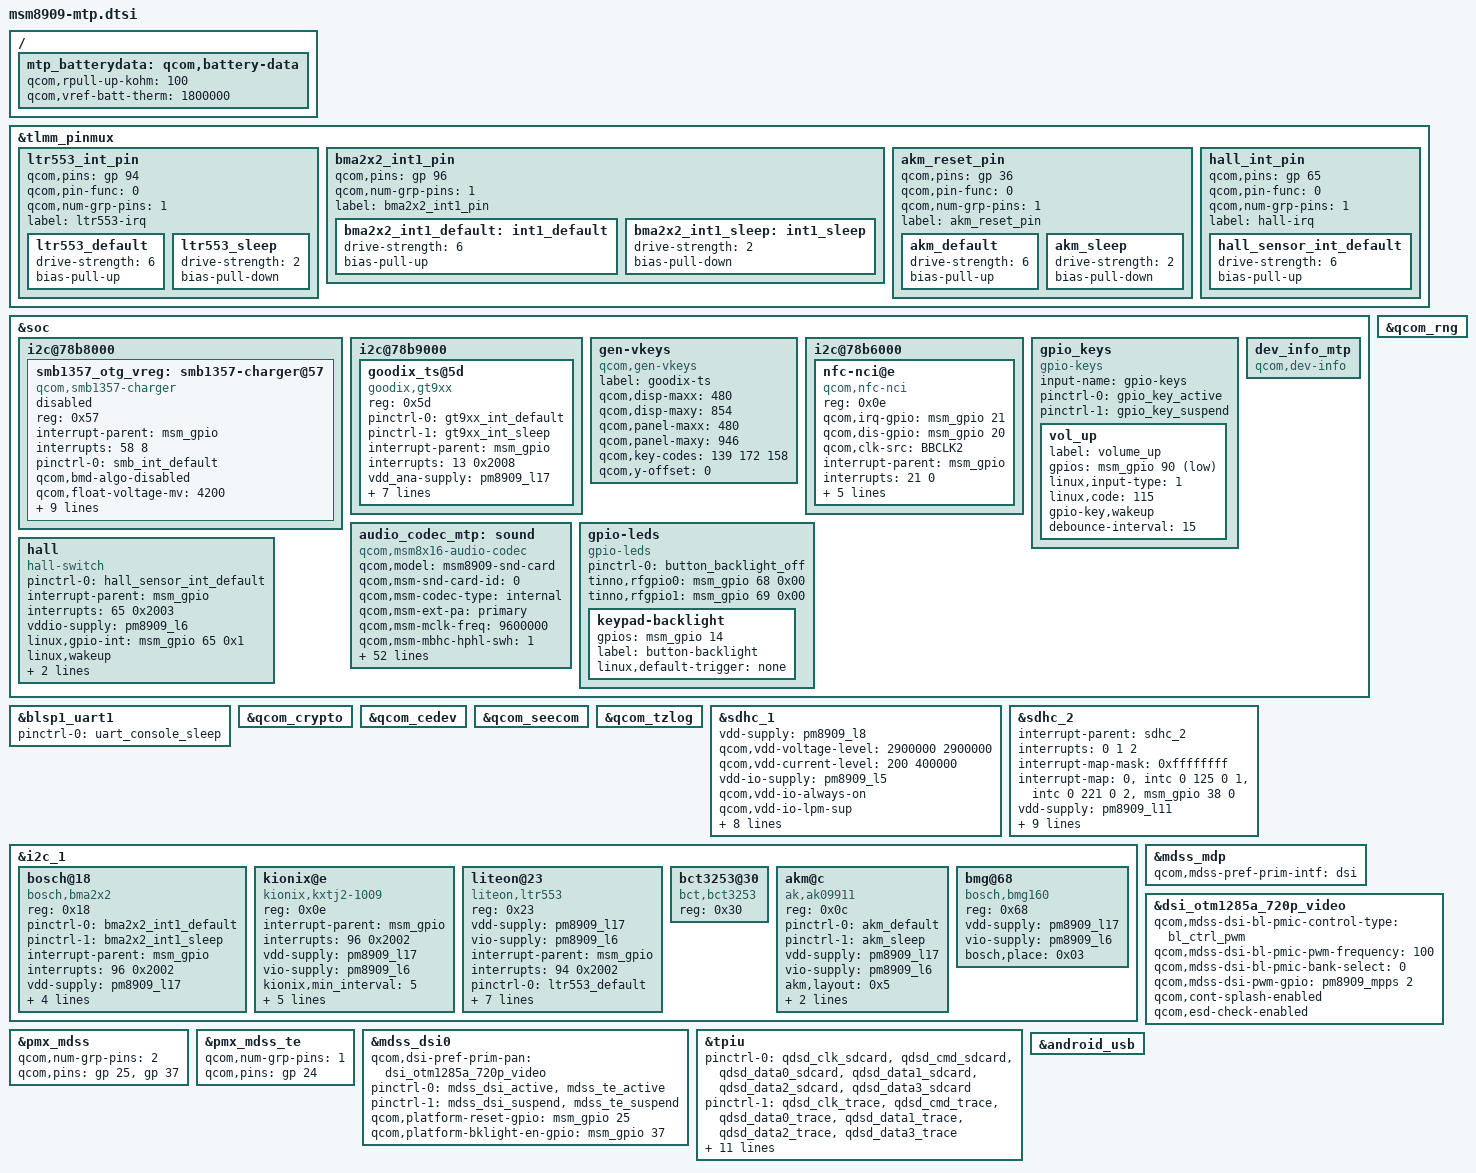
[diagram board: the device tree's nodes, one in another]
/* Copyright (c) 2014-2015, The Linux Foundation. All rights reserved.
 *
 * This program is free software; you can redistribute it and/or modify
 * it under the terms of the GNU General Public License version 2 and
 * only version 2 as published by the Free Software Foundation.
 *
 * This program is distributed in the hope that it will be useful,
 * but WITHOUT ANY WARRANTY; without even the implied warranty of
 * MERCHANTABILITY or FITNESS FOR A PARTICULAR PURPOSE.  See the
 * GNU General Public License for more details.
 */

#include "msm8909.dtsi"
#include "msm8909-pinctrl.dtsi"
#include "msm8909-camera-sensor-mtp.dtsi"
//[JST_SRC START BY CY][20150226][Sensors dts config]
&tlmm_pinmux {

	ltr553_int_pin {
		qcom,pins = <&gp 94>;
		qcom,pin-func = <0>;
		qcom,num-grp-pins = <1>;
		label = "ltr553-irq";
		ltr553_default: ltr553_default {
			drive-strength = <6>;
			bias-pull-up;
		};
		ltr553_sleep: ltr553_sleep {
			drive-strength = <2>;
			bias-pull-down;
		};

	};

	bma2x2_int1_pin {
		qcom,pins = <&gp 96>;
		qcom,num-grp-pins = <1>;
		label = "bma2x2_int1_pin";
		bma2x2_int1_default: int1_default {
			  drive-strength = <6>;
			  bias-pull-up;
		};
		bma2x2_int1_sleep: int1_sleep {
			  drive-strength = <2>;
			  bias-pull-down;
		};
	};

	akm_reset_pin {
		qcom,pins = <&gp 36>;
		qcom,pin-func = <0>;
		qcom,num-grp-pins = <1>;
		label = "akm_reset_pin";
		akm_default: akm_default {
			drive-strength = <6>;
			bias-pull-up;
		};
		akm_sleep: akm_sleep {
			drive-strength = <2>;
			bias-pull-down;
		};
	};
	
	hall_int_pin {
		qcom,pins = <&gp 65>;
		qcom,pin-func = <0>;
		qcom,num-grp-pins = <1>;
		label = "hall-irq";
		hall_sensor_int_default: hall_sensor_int_default {
			drive-strength = <6>;
			bias-pull-up;
		};
	};
};
//[JST_SRC END][20150226]
&soc {
	/*
	 * DT node to add support for SMB135x charger and integrate
	 * with VM-BMS.
	 */
	i2c@78b8000 {
		smb1357_otg_vreg: smb1357-charger@57 {
			compatible = "qcom,smb1357-charger";
			reg = <0x57>;
			interrupt-parent = <&msm_gpio>;
			interrupts = <58 8>;
			pinctrl-names = "default";
			pinctrl-0 = <&smb_int_default>;

			qcom,bmd-algo-disabled;
			qcom,float-voltage-mv = <4200>;
			qcom,charging-timeout = <1536>;
			qcom,recharge-thresh-mv = <100>;
			regulator-name = "smb1357_otg_vreg";
			qcom,soft-vfloat-comp-disabled;
			qcom,thermal-mitigation = <1500 700 600 0>;

			qcom,bms-psy-name = "bms";

			/*
			 * Disable SMB1357 based charging termination as BMS
			 * controls charging.
			 */
			qcom,iterm-disabled;

			/*
			 * Disable charge inhibit feature to start chargin on
			 * charger insertion independent of battery voltage.
			 */
			qcom,inhibit-disabled;

			/* BMS is controlling charging/re-charge */
			qcom,bms-controlled-charging;

			/*
			 * To enable charger node:
			 * set status = "ok" and
			 * add 'qcom,use-external-charger' to pm8909_chg node
			 */
			status = "disabled";
		};
	};

	i2c@78b9000 { /* BLSP1 QUP5 */
	/*	synaptics@20 {
			compatible = "synaptics,dsx";
			reg = <0x20>;
			interrupt-parent = <&msm_gpio>;
			interrupts = <13 0x2008>;
			avdd-supply = <&pm8909_l17>;
			vdd-supply = <&pm8909_l6>;
			pinctrl-names = "pmx_ts_active","pmx_ts_suspend","pmx_ts_release";
			pinctrl-0 = <&ts_int_active &ts_reset_active>;
			pinctrl-1 = <&ts_int_suspend &ts_reset_suspend>;
			pinctrl-2 = <&ts_release>;
			synaptics,irq-gpio = <&msm_gpio 13 0x2008>;
			synaptics,reset-gpio = <&msm_gpio 12 0x0>;
			synaptics,disable-gpios;
			synaptics,display-coords = <0 0 719 1279>;
			synaptics,panel-coords = <0 0 719 1405>;
		};*/
		goodix_ts@5d {
			compatible = "goodix,gt9xx";
			reg = <0x5d>;
			pinctrl-names ="gt9xx_int_pin_active" ,"gt9xx_int_pin_suspend";
			pinctrl-0 = <&gt9xx_int_default>;
			pinctrl-1 = <&gt9xx_int_sleep>;			
			interrupt-parent = <&msm_gpio>;
			interrupts = <13 0x2008>;
			vdd_ana-supply = <&pm8909_l17>;
			vcc_i2c-supply = <&pm8909_l6>;
			goodix,rst-gpio = <&msm_gpio 12 0x00>;
			goodix,irq-gpio = <&msm_gpio 13 0x00>;
			goodix,cfg-group0 = [ 
  45  D0  02  00  05  05  05  40  01  08  28
  08  50  32  03  09  00  00  FF  67  01  00
  06  00  00  00  00  8A  2A  0B  29  2B  D5
  09  00  42  00  42  33  1D  00  01  00  00
  00  00  00  32  15  00  2B  14  50  94  C5
  02  00  00  00  04  D3  17  00  A7  1E  00
  82  28  00  67  35  00  53  46  00  53  00
  00  00  00  00  00  00  00  00  00  00  00
  00  00  00  00  00  00  00  00  00  00  00
  00  00  00  00  00  00  00  00  0C  00  00
  00  00  12  10  0E  08  0A  0C  14  16  02
  04  06  FF  FF  FF  00  00  00  00  00  00
  00  00  00  00  06  00  00  00  00  00  22
  16  21  18  20  1C  1F  1D  24  1E  12  00
  02  10  04  0F  06  0C  08  0A  FF  FF  FF
  FF  FF  FF  00  00  00  F4  FF  FF  FF  FF
  FF  FF  FF  FF  7F  FF  FF  FF  0F  01];

			goodix,cfg-group1 = [
  45  D0  02  00  05  05  05  40  01  08  28
  08  50  32  03  09  00  00  FF  67  01  00
  06  00  00  00  00  8A  2A  0B  29  2B  D5
  09  00  42  00  42  33  1D  00  01  00  00
  00  00  00  32  15  00  2B  14  50  94  C5
  02  00  00  00  04  D3  17  00  A7  1E  00
  82  28  00  67  35  00  53  46  00  53  00
  00  00  00  00  00  00  00  00  00  00  00
  00  00  00  00  00  00  00  00  00  00  00
  00  00  00  00  00  00  00  00  0C  00  00
  00  00  12  10  0E  08  0A  0C  14  16  02
  04  06  FF  FF  FF  00  00  00  00  00  00
  00  00  00  00  06  00  00  00  00  00  22
  16  21  18  20  1C  1F  1D  24  1E  12  00
  02  10  04  0F  06  0C  08  0A  FF  FF  FF
  FF  FF  FF  00  00  00  F4  FF  FF  FF  FF
  FF  FF  FF  FF  7F  FF  FF  FF  0F  01];
		};

	};

	gen-vkeys {
		compatible = "qcom,gen-vkeys";
		label = "goodix-ts";
		qcom,disp-maxx = <480>;
		qcom,disp-maxy = <854>;
		qcom,panel-maxx = <480>;
		qcom,panel-maxy = <946>;
		qcom,key-codes = <139 172 158>;
		qcom,y-offset = <0>;
	};

	i2c@78b6000 { /* BLSP1 QUP2 */
		nfc-nci@e {
			compatible = "qcom,nfc-nci";
			reg = <0x0e>;
			qcom,irq-gpio = <&msm_gpio 21 0x00>;
			qcom,dis-gpio = <&msm_gpio 20 0x00>;
			qcom,clk-src = "BBCLK2";
			interrupt-parent = <&msm_gpio>;
			interrupts = <21 0>;
			interrupt-names = "nfc_irq";
			pinctrl-names = "nfc_active","nfc_suspend";
			pinctrl-0 = <&nfc_int_active &nfc_disable_active>;
			pinctrl-1 = <&nfc_int_suspend &nfc_disable_suspend>;
			qcom,clk-gpio = <&pm8909_gpios 2 0>;
			clocks = <&clock_rpm clk_bb_clk2_pin>;
			clock-names = "ref_clk";
		};
	};

	gpio_keys {
		compatible = "gpio-keys";
		input-name = "gpio-keys";
		pinctrl-names = "tlmm_gpio_key_active","tlmm_gpio_key_suspend";
		pinctrl-0 = <&gpio_key_active>;
		pinctrl-1 = <&gpio_key_suspend>;

  //Tinno cancel by shilei
	/*	camera_focus {
			label = "camera_focus";
			gpios = <&msm_gpio 91 0x1>;
			linux,input-type = <1>;
			linux,code = <0x210>;
			gpio-key,wakeup;
			debounce-interval = <15>;
		};

		camera_snapshot {
			label = "camera_snapshot";
			gpios = <&msm_gpio 92 0x1>;
			linux,input-type = <1>;
			linux,code = <0x2fe>;
			gpio-key,wakeup;
			debounce-interval = <15>;
		};
*/
		vol_up {
			label = "volume_up";
			gpios = <&msm_gpio 90 0x1>;
			linux,input-type = <1>;
			linux,code = <115>;
			gpio-key,wakeup;
			debounce-interval = <15>;
		};
	};
//add for tinno devinfo
       dev_info_mtp{
		compatible = "qcom,dev-info";
       };
//add end
	audio_codec_mtp: sound {
		compatible = "qcom,msm8x16-audio-codec";
		qcom,model = "msm8909-snd-card";
		qcom,msm-snd-card-id = <0>;
		qcom,msm-codec-type = "internal";
		qcom,msm-ext-pa = "primary";
		qcom,msm-mclk-freq = <9600000>;
		qcom,msm-mbhc-hphl-swh = <1>;//headset det TN:peter
		qcom,msm-mbhc-gnd-swh = <0>;
		qcom,msm-hs-micbias-type = "internal";
		qcom,msm-micbias1-ext-cap;
		qcom,msm-spk-ext-pa = <&msm_gpio 98 0>;//external pa TN:Peter
		qcom,audio-routing =
			"RX_BIAS", "MCLK",
			"SPK_RX_BIAS", "MCLK",
			"INT_LDO_H", "MCLK",
			"MIC BIAS Internal1", "Handset Mic",//headset mic TN:peter
			"MIC BIAS Internal2", "Headset Mic",
			"MIC BIAS External", "Secondary Mic",
			"AMIC1", "MIC BIAS Internal1",//phone mic TN:peter
			"AMIC2", "MIC BIAS Internal2",
			"AMIC3", "MIC BIAS External";
		pinctrl-names = "cdc_lines_act",
				"cdc_lines_sus",
				"cross_conn_det_act",
				"cross_conn_det_sus";
		pinctrl-0 = <&cdc_pdm_lines_act  &cdc_ext_spk_pa_act>;//external pa TN:Peter
		pinctrl-1 = <&cdc_pdm_lines_sus  &cdc_ext_spk_pa_sus>;//external pa TN:Peter
		pinctrl-2 = <&cross_conn_det_act>;
		pinctrl-3 = <&cross_conn_det_sus>;
		qcom,cdc-us-euro-gpios = <&msm_gpio 97 0>;
		asoc-platform = <&pcm0>, <&pcm1>, <&voip>, <&voice>,
				<&loopback>, <&compress>, <&hostless>,
				<&afe>, <&lsm>, <&routing>, <&lpa>,
				<&voice_svc>;
		asoc-platform-names = "msm-pcm-dsp.0", "msm-pcm-dsp.1",
				"msm-voip-dsp", "msm-pcm-voice", "msm-pcm-loopback",
				"msm-compress-dsp", "msm-pcm-hostless", "msm-pcm-afe",
				"msm-lsm-client", "msm-pcm-routing", "msm-pcm-lpa",
				"msm-voice-svc";
		asoc-cpu = <&dai_pri_auxpcm>, <&dai_hdmi>,
				<&dai_mi2s0>, <&dai_mi2s1>, <&dai_mi2s2>, <&dai_mi2s3>,
				<&sb_0_rx>, <&sb_0_tx>, <&sb_1_rx>, <&sb_1_tx>,
				<&sb_3_rx>, <&sb_3_tx>, <&sb_4_rx>, <&sb_4_tx>,
				<&bt_sco_rx>, <&bt_sco_tx>, <&int_fm_rx>, <&int_fm_tx>,
				<&afe_pcm_rx>, <&afe_pcm_tx>, <&afe_proxy_rx>, <&afe_proxy_tx>,
				<&incall_record_rx>, <&incall_record_tx>, <&incall_music_rx>,
				<&incall_music_2_rx>;
		asoc-cpu-names = "msm-dai-q6-auxpcm.1", "msm-dai-q6-hdmi.8",
				"msm-dai-q6-mi2s.0", "msm-dai-q6-mi2s.1",
				"msm-dai-q6-mi2s.2", "msm-dai-q6-mi2s.3",
				"msm-dai-q6-dev.16384", "msm-dai-q6-dev.16385",
				"msm-dai-q6-dev.16386", "msm-dai-q6-dev.16387",
				"msm-dai-q6-dev.16390", "msm-dai-q6-dev.16391",
				"msm-dai-q6-dev.16392", "msm-dai-q6-dev.16393",
				"msm-dai-q6-dev.12288", "msm-dai-q6-dev.12289",
				"msm-dai-q6-dev.12292", "msm-dai-q6-dev.12293",
				"msm-dai-q6-dev.224", "msm-dai-q6-dev.225",
				"msm-dai-q6-dev.241", "msm-dai-q6-dev.240",
				"msm-dai-q6-dev.32771", "msm-dai-q6-dev.32772",
				"msm-dai-q6-dev.32773", "msm-dai-q6-dev.32770";
		asoc-codec = <&stub_codec>, <&pm8909_conga_dig>;
		asoc-codec-names = "msm-stub-codec.1", "tombak_codec";
	};
	//yajun add button led
	gpio-leds {
		compatible = "gpio-leds";
		status = "okay";
		pinctrl-0 = <&button_backlight_off>;
		
		tinno,rfgpio0 = <&msm_gpio 68 0x00>;              //gpio for tinno rf version 
		tinno,rfgpio1 = <&msm_gpio 69 0x00>;		      //gpio for tinno rf version 
		
		keypad-backlight {
			gpios = <&msm_gpio 14 0>;
			label = "button-backlight";
			linux,default-trigger = "none";
		};
	};
	//[JST_SRC START BY CY][20150226][Sensors hall config]
	hall {
		compatible = "hall-switch";
		pinctrl-names = "default";
		pinctrl-0 = <&hall_sensor_int_default>;
		interrupt-parent = <&msm_gpio>;
		interrupts = <65 0x2003>;
		vddio-supply = <&pm8909_l6>;
		linux,gpio-int = <&msm_gpio 65 0x1>;
		linux,wakeup;
		linux,min-uv = <1650000>;
		linux,max-uv = <3300000>;
	};
	//[JST_SRC END][20150226]
};

&blsp1_uart1 {
/*	status = "disabled";*/
	pinctrl-names = "default";
	pinctrl-0 = <&uart_console_sleep>;
};

/ {
	mtp_batterydata: qcom,battery-data {
		qcom,rpull-up-kohm = <100>;
		qcom,vref-batt-therm = <1800000>;

		#include "batterydata-qrd-4v35-2500mah.dtsi"
	};
};

&qcom_rng {
	status = "okay";
};

&qcom_crypto {
	status = "okay";
};

&qcom_cedev {
	status = "okay";
};

&qcom_seecom {
	status = "okay";
};

&qcom_tzlog {
	status = "okay";
};

&sdhc_1 {
	vdd-supply = <&pm8909_l8>;
	qcom,vdd-voltage-level = <2900000 2900000>;
	qcom,vdd-current-level = <200 400000>;

	vdd-io-supply = <&pm8909_l5>;
	qcom,vdd-io-always-on;
	qcom,vdd-io-lpm-sup;
	qcom,vdd-io-voltage-level = <1800000 1800000>;
	qcom,vdd-io-current-level = <200 60000>;

	pinctrl-names = "active", "sleep";
	pinctrl-0 = <&sdc1_clk_on &sdc1_cmd_on &sdc1_data_on>;
	pinctrl-1 = <&sdc1_clk_off &sdc1_cmd_off &sdc1_data_off>;

	qcom,bus-speed-mode = "HS200_1p8v", "DDR_1p8v";
	qcom,nonremovable;

	status = "ok";
};

&sdhc_2 {
	 #address-cells = <0>;
	interrupt-parent = <&sdhc_2>;
	interrupts = <0 1 2>;
	#interrupt-cells = <1>;
	interrupt-map-mask = <0xffffffff>;
	interrupt-map = <0 &intc 0 125 0
			1 &intc 0 221 0
			2 &msm_gpio 38 0>;
	interrupt-names = "hc_irq", "pwr_irq", "status_irq";
	// cd-gpios = <&msm_gpio 38 0x1>;

	vdd-supply = <&pm8909_l11>;
	qcom,vdd-voltage-level = <1800000 2950000>;
	qcom,vdd-current-level = <15000 400000>;

	vdd-io-supply = <&pm8909_l12>;
	qcom,vdd-io-voltage-level = <1800000 2950000>;
	qcom,vdd-io-current-level = <200 50000>;

	pinctrl-names = "active", "sleep";
	pinctrl-0 = <&sdc2_clk_on &sdc2_cmd_on &sdc2_data_on &sdc2_cd_on>;
	pinctrl-1 = <&sdc2_clk_off &sdc2_cmd_off &sdc2_data_off &sdc2_cd_off>;

	status = "ok";
};
//[JST_SRC START BY CY][20150225][Sensors dts config]
&i2c_1 { /* BLSP1 QUP1 */
	bosch@18 { /* Accelerometer sensor */
		compatible = "bosch,bma2x2";
		reg = <0x18>;
		pinctrl-names = "bma_default","bma_sleep";
		pinctrl-0 = <&bma2x2_int1_default>;
		pinctrl-1 = <&bma2x2_int1_sleep >;
		interrupt-parent = <&msm_gpio>;
		interrupts = <96 0x2002>;
		vdd-supply = <&pm8909_l17>;
		vio-supply = <&pm8909_l6>;
		bosch,init-interval = <200>;
		bosch,place = <0x7>;
		bosch,gpio-int1 = <&msm_gpio 96 0x2002>;
	};
	
	kionix@e {
		compatible = "kionix,kxtj2-1009";
		reg = <0x0e>;
		interrupt-parent = <&msm_gpio>;
		interrupts = <96 0x2002>;
		vdd-supply = <&pm8909_l17>;
		vio-supply = <&pm8909_l6>;
		kionix,min_interval = <5>;
		kionix,poll_interval = <100>;
		kionix,accel_direction = <7>;
		kionix,accel_irq_use_drdy = <0>;
		kionix,accel_res = <12>;
		kionix,accel_g_range = <2>;
	};

	liteon@23 {
		compatible = "liteon,ltr553";
		reg = <0x23>;
		vdd-supply = <&pm8909_l17>;
		vio-supply = <&pm8909_l6>;
		interrupt-parent = <&msm_gpio>;
		interrupts = <94 0x2002>;
		pinctrl-names = "default","sleep";
		pinctrl-0 = <&ltr553_default>;
		pinctrl-1 = <&ltr553_sleep>;
		liteon,intr = <&msm_gpio 94 0x2002>;
		liteon,highthr = <1040>;
		liteon,lowthr = <1020>;
		tinno,base_value = <0x3FF>;
		tinno,threshold_high_offset = <0x70>;
		tinno,threshold_low_offset = <0x55>;
	};

	bct3253@30 { /* Ambient light and proximity sensor */
		compatible = "bct,bct3253";
		reg = <0x30>;
	};


	akm@c { /* Magnetic field sensor */
		compatible = "ak,ak09911";
		reg = <0x0c>;
		pinctrl-names = "default","sleep";
		pinctrl-0 = <&akm_default>;
		pinctrl-1 = <&akm_sleep>;
		vdd-supply = <&pm8909_l17>;
		vio-supply = <&pm8909_l6>;
		akm,layout = <0x5>;
		akm,gpio_rstn = <&msm_gpio 36 0x0>;
		akm,auto-report;
	};
	bmg@68 { /* GYROSCOPE sensor */
		compatible = "bosch,bmg160";
		reg = <0x68>;
		vdd-supply = <&pm8909_l17>;
		vio-supply = <&pm8909_l6>;
		bosch,place = <0x03>;
	};
};
//[JST_SRC END][20150225]

//#include "dsi-panel-hx8394d-720p-video.dtsi"
//#include "dsi-panel-hx8394d-qhd-video.dtsi"
//yajun lcd
#include "dsi-panel-otm1285a-720p-video.dtsi"

&mdss_mdp {
	qcom,mdss-pref-prim-intf = "dsi";
};

/*
&dsi_hx8394d_720_vid {
	qcom,mdss-dsi-bl-pmic-control-type = "bl_ctrl_pwm";
	qcom,mdss-dsi-bl-pmic-pwm-frequency = <100>;
	qcom,mdss-dsi-bl-pmic-bank-select = <0>;
	qcom,mdss-dsi-pwm-gpio = <&pm8909_mpps 2 0>;
	qcom,cont-splash-enabled;
};

&dsi_hx8394d_qhd_vid {
	qcom,mdss-dsi-bl-pmic-control-type = "bl_ctrl_pwm";
	qcom,mdss-dsi-bl-pmic-pwm-frequency = <100>;
	qcom,mdss-dsi-bl-pmic-bank-select = <0>;
	qcom,mdss-dsi-pwm-gpio = <&pm8909_mpps 2 0>;
	qcom,cont-splash-enabled;
};*/

&dsi_otm1285a_720p_video {
	qcom,mdss-dsi-bl-pmic-control-type = "bl_ctrl_pwm";
	qcom,mdss-dsi-bl-pmic-pwm-frequency = <100>;
	qcom,mdss-dsi-bl-pmic-bank-select = <0>;
	qcom,mdss-dsi-pwm-gpio = <&pm8909_mpps 2 0>;
	qcom,cont-splash-enabled;
	qcom,esd-check-enabled;
};

&pmx_mdss {
	qcom,num-grp-pins = <2>;
	qcom,pins = <&gp 25>, <&gp 37>;
};

&pmx_mdss_te {
	qcom,num-grp-pins = <1>;
	qcom,pins = <&gp 24>;
};

&mdss_dsi0 {
	qcom,dsi-pref-prim-pan = <&dsi_otm1285a_720p_video>;
	pinctrl-names = "mdss_default", "mdss_sleep";
	pinctrl-0 = <&mdss_dsi_active &mdss_te_active>;
	pinctrl-1 = <&mdss_dsi_suspend &mdss_te_suspend>;

	qcom,platform-reset-gpio = <&msm_gpio 25 0>;
	qcom,platform-bklight-en-gpio = <&msm_gpio 37 0>;
};

/* CoreSight */
&tpiu {
	pinctrl-names = "sdcard", "trace", "swduart",
			"swdtrc", "jtag", "spmi";
	/* NIDnT */
	pinctrl-0 = <&qdsd_clk_sdcard &qdsd_cmd_sdcard
		     &qdsd_data0_sdcard &qdsd_data1_sdcard
		     &qdsd_data2_sdcard &qdsd_data3_sdcard>;
	pinctrl-1 = <&qdsd_clk_trace &qdsd_cmd_trace
		     &qdsd_data0_trace &qdsd_data1_trace
		     &qdsd_data2_trace &qdsd_data3_trace>;
	pinctrl-2 = <&qdsd_cmd_swduart &qdsd_data0_swduart
		     &qdsd_data1_swduart &qdsd_data2_swduart
		     &qdsd_data3_swduart>;
	pinctrl-3 = <&qdsd_clk_swdtrc &qdsd_cmd_swdtrc
		     &qdsd_data0_swdtrc &qdsd_data1_swdtrc
		     &qdsd_data2_swdtrc &qdsd_data3_swdtrc>;
	pinctrl-4 = <&qdsd_cmd_jtag &qdsd_data0_jtag
		     &qdsd_data1_jtag &qdsd_data2_jtag
		     &qdsd_data3_jtag>;
	pinctrl-5 = <&qdsd_clk_spmi &qdsd_cmd_spmi
		     &qdsd_data0_spmi &qdsd_data3_spmi>;
};
//[JST_SRC START BY CY][20150317][cdrom dts config]
&android_usb {
        //qcom,android-usb-cdrom;
};
//[JST_SRC END][20150317]
